# AT32F421 register map
Vendor: Keil; Series: AT32F421; File version: 1.0
CPU: CM4 r0p1, little endian, no MPU, FPU, 4 interrupt priority bits
Registers are 32-bit, read-write, reset 0x0 unless marked. A register's access mark holds for its fields unless they carry their own. Offsets are from the block's base; [hi:lo] are bit positions; {n}, {i} and the like mark numbered series.

## GPIOA — General purpose I/Os
Base 0x48000000
Same registers: GPIOB 0x48000400, GPIOC 0x48000800, GPIOF 0x48001400
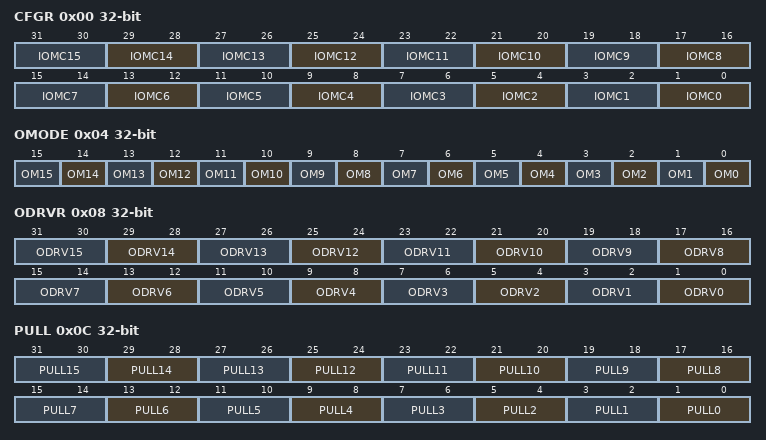
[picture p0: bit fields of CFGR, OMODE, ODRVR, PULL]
0x00 CFGR — GPIO function configurate register. **WARNING**: `reset()` writes the hardware reset value which does NOT account for SWD/JTAG pin default configuration. Calling `reset()` may disable debug access to the MCU.
  [2n+1:2n] IOMC{n} (n=0..15) — GPIOx pin {n} mode configurate
    0=Input mode; 1=Output (General-purpose output mode); 2=Multiplexed function mode; 3=Analog mode
0x04 OMODE — GPIO output mode register
  [n] OM{n} (n=0..15) — GPIOx pin {n} output mode configurate
    0=PushPull; 1=OpenDrain
0x08 ODRVR — GPIO drive capability register
  [2n+1:2n] ODRV{n} (n=0..15) — GPIOx pin {n} output drive capability
    1=Large sourcing/sinking strength; other=Normal sourcing/sinking strength
0x0C PULL — GPIO pull-up/pull-down register. **WARNING**: `reset()` writes the hardware reset value which does NOT account for SWD/JTAG pin default configuration. Calling `reset()` may disable debug access to the MCU.
  [2n+1:2n] PULL{n} (n=0..15) — GPIOx pin {n} pull configuration
    0=No pull-up/pull-down; 1=PullUp; 2=PullDown
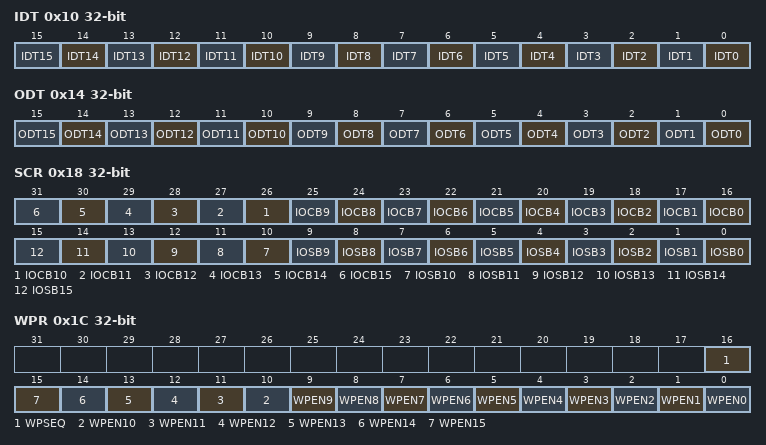
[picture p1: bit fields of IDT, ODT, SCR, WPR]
0x10 IDT ro — GPIO input data register
  [n] IDT{n} (n=0..15) — Port input data
    0=Low (Input is logic low); 1=High (Input is logic high)
0x14 ODT — GPIO output data register
  [n] ODT{n} (n=0..15) — Port output data
    on read: 0=PullDown; 1=PullUp | on write: 0=Low (Set output to logic low); 1=High (Set output to logic high)
0x18 SCR wo — Port bit set/clear register
  [n+16] IOCB{n} (n=0..15) write-1-clears — Clear bit {n}
    1=Clear the corresponding ODT bit
  [n] IOSB{n} (n=0..15) write-1-sets — Set bit {n}
    1=Set (Set the corresponding ODT bit)
0x1C WPR — Port write protect register
  [16] WPSEQ — Write protect sequence
    0=Clear; 1=Set
  [n] WPEN{n} (n=0..15) — Write protect enable {n}
    on read: 0=NotProtected (Port is not write protected); 1=Protected (Port is write protected) | on write: 0=NoProtect (No effect); 1=Protect (Write protect)
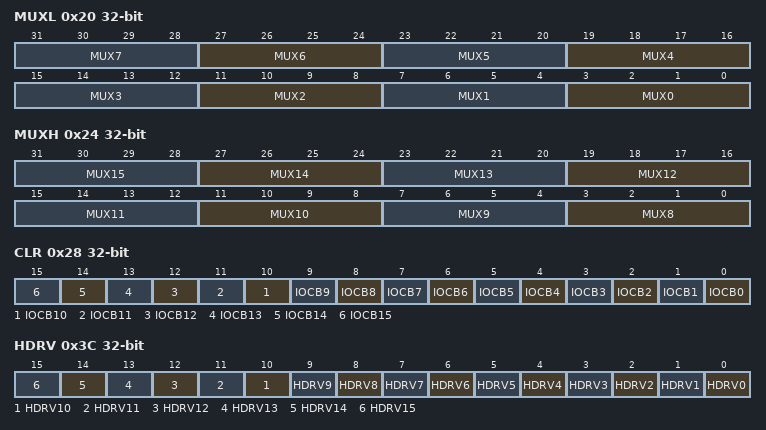
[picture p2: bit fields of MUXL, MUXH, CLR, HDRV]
0x20 MUXL — GPIO muxing function low register
  [4n+3:4n] MUX{n} (n=0..7) — GPIOx pin {n} muxing
0x24 MUXH — GPIO muxing function high register
  [4n-29:4n-32] MUX{n} (n=8..15) — GPIOx pin {n} muxing
0x28 CLR wo — GPIO bit reset register
  [n] IOCB{n} (n=0..15) write-1-clears — Clear bit {n}
    1=Clear the corresponding ODT bit
0x3C HDRV — Huge current driver
  [n] HDRV{n} (n=0..15) — Port x driver bit y
    0=Normal/large drive strength (according to ODRVR); 1=Huge (GPIO is configured as maximum sourcing/sinking strength)

## EXINT
Base 0x40010400
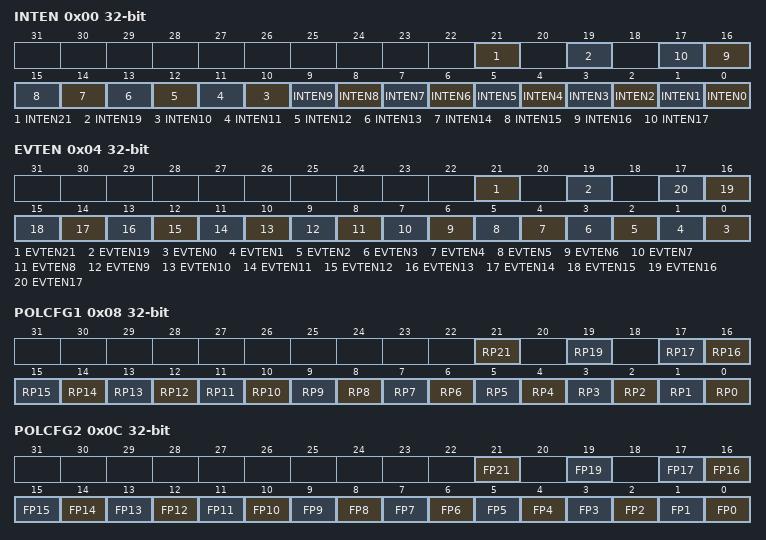
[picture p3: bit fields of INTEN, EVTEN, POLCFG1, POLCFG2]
0x00 INTEN — Interrupt enable register (EXTINT_INTEN)
  [all] fields
    on read: 0=Disabled (Interrupt request is disabled); 1=Enabled (Interrupt request is enabled) | on write: 0=Disable (Interrupt request disable); 1=Enable (Interrupt request enable)
  [21] INTEN21 — Interrupt enable or disable on line 21
  [19] INTEN19 — Interrupt enable or disable on line 19
  [n] INTEN{n} (n=0..17) — Interrupt enable or disable on line {n}
0x04 EVTEN — Event enable register (EXTINT_EVTEN)
  [all] fields
    on read: 0=Disabled (Event request is disabled); 1=Enabled (Event request is enabled) | on write: 0=Disable (Event request disable); 1=Enable (Event request enable)
  [21] EVTEN21 — Event enable or disable on line 21
  [19] EVTEN19 — Event enable or disable on line 19
  [n] EVTEN{n} (n=0..17) — Event enable or disable on line {n}
0x08 POLCFG1 — Rising polarity configuration register(EXTINT_POLCFG1)
  [all] fields
    on read: 0=Disabled (Rising trigger is disabled); 1=Enabled (Rising trigger is enabled) | on write: 0=Disable (Rising trigger disable); 1=Enable (Rising trigger enable)
  [21] RP21 — Rising polarity configuration bit of line 21
  [19] RP19 — Rising polarity configuration bit of line 19
  [n] RP{n} (n=0..17) — Rising polarity configuration bit on line {n}
0x0C POLCFG2 — Falling polarity configuration register(EXTINT_POLCFG2)
  [all] fields
    on read: 0=Disabled (Falling trigger is disabled); 1=Enabled (Falling trigger is enabled) | on write: 0=Disable (Falling trigger disable); 1=Enable (Falling trigger enable)
  [21] FP21 — Falling polarity event configuration bit of line 21
  [19] FP19 — Falling polarity event configuration bit of line 19
  [n] FP{n} (n=0..17) — Falling polarity configuration bit on line {n}
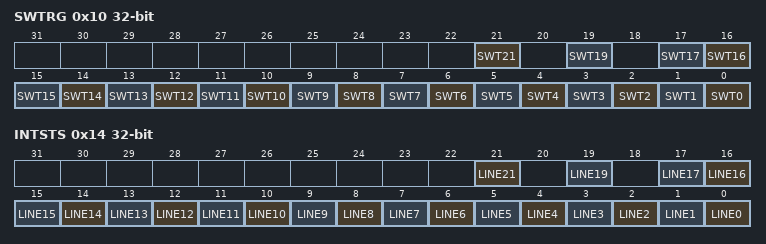
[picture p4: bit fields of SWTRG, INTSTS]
0x10 SWTRG — Software trigger register
  [all] fields
    on read: 0=NoTrigger (Default value); 1=Triggered (Software trigger generated) | on write: 1=Trigger (Generate trigger)
  [21] SWT21 write-1-sets — Software triggle on line 21
  [19] SWT19 write-1-sets — Software triggle on line 19
  [n] SWT{n} (n=0..17) write-1-sets — Software trigger on line {n}
0x14 INTSTS — Interrupt status register (EXTINT_INTSTS)
  [all] fields
    on read: 0=No interrupt occurred; 1=Interrupt occurred | on write: 1=Clear status flag
  [21] LINE21 write-1-clears — Line 21 state bit
  [19] LINE19 write-1-clears — Line 19 state bit
  [n] LINE{n} (n=0..17) write-1-clears — Line {n} status bit
